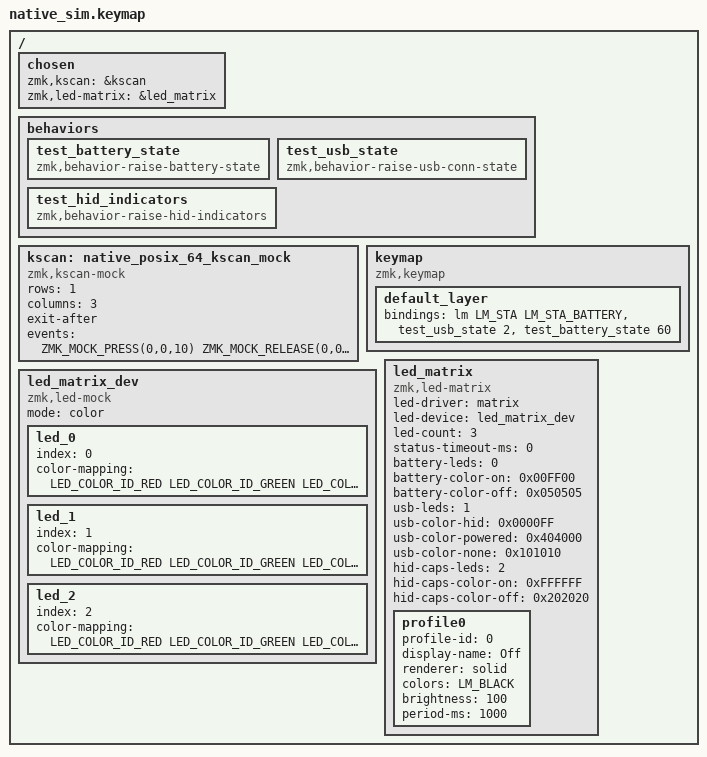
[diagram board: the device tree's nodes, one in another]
#include <dt-bindings/zmk/keys.h>
#include <dt-bindings/zmk/kscan_mock.h>
#include <dt-bindings/zmk/led_matrix.h>
#include <dt-bindings/zmk/led_matrix_colors.h>
#include <dt-bindings/led/led.h>
#include <behaviors.dtsi>

/ {
    chosen {
        zmk,kscan = &kscan;
        zmk,led-matrix = &led_matrix;
    };

    behaviors {
        test_battery_state: test_battery_state {
            compatible = "zmk,behavior-raise-battery-state";
            #binding-cells = <1>;
        };

        test_usb_state: test_usb_state {
            compatible = "zmk,behavior-raise-usb-conn-state";
            #binding-cells = <1>;
        };

        test_hid_indicators: test_hid_indicators {
            compatible = "zmk,behavior-raise-hid-indicators";
            #binding-cells = <1>;
        };
    };

    kscan: native_posix_64_kscan_mock {
        compatible = "zmk,kscan-mock";
        rows = <1>;
        columns = <3>;
        exit-after;
        events = <
            ZMK_MOCK_PRESS(0,0,10)
            ZMK_MOCK_RELEASE(0,0,20)
            ZMK_MOCK_PRESS(0,1,80)
            ZMK_MOCK_RELEASE(0,1,20)
            ZMK_MOCK_PRESS(0,2,80)
            ZMK_MOCK_RELEASE(0,2,20)
        >;
    };

    keymap {
        compatible = "zmk,keymap";

        default_layer {
            bindings = <
                &lm LM_STA LM_STA_BATTERY
                &test_usb_state 2
                &test_battery_state 60
            >;
        };
    };

    led_matrix_dev: led_matrix_dev {
        compatible = "zmk,led-mock";
        mode = "color";

        led_0 { index = <0>; color-mapping = <LED_COLOR_ID_RED LED_COLOR_ID_GREEN LED_COLOR_ID_BLUE>; };
        led_1 { index = <1>; color-mapping = <LED_COLOR_ID_RED LED_COLOR_ID_GREEN LED_COLOR_ID_BLUE>; };
        led_2 { index = <2>; color-mapping = <LED_COLOR_ID_RED LED_COLOR_ID_GREEN LED_COLOR_ID_BLUE>; };
    };

    led_matrix: led_matrix {
        compatible = "zmk,led-matrix";
        led-driver = "matrix";
        led-device = <&led_matrix_dev>;
        led-count = <3>;
        status-timeout-ms = <0>;
        battery-leds = <0>;
        battery-color-on = <0x00FF00>;
        battery-color-off = <0x050505>;
        usb-leds = <1>;
        usb-color-hid = <0x0000FF>;
        usb-color-powered = <0x404000>;
        usb-color-none = <0x101010>;
        hid-caps-leds = <2>;
        hid-caps-color-on = <0xFFFFFF>;
        hid-caps-color-off = <0x202020>;

        profile0 {
            profile-id = <0>;
            display-name = "Off";
            renderer = "solid";
            colors = <LM_BLACK>;
            brightness = <100>;
            period-ms = <1000>;
        };
    };
};
